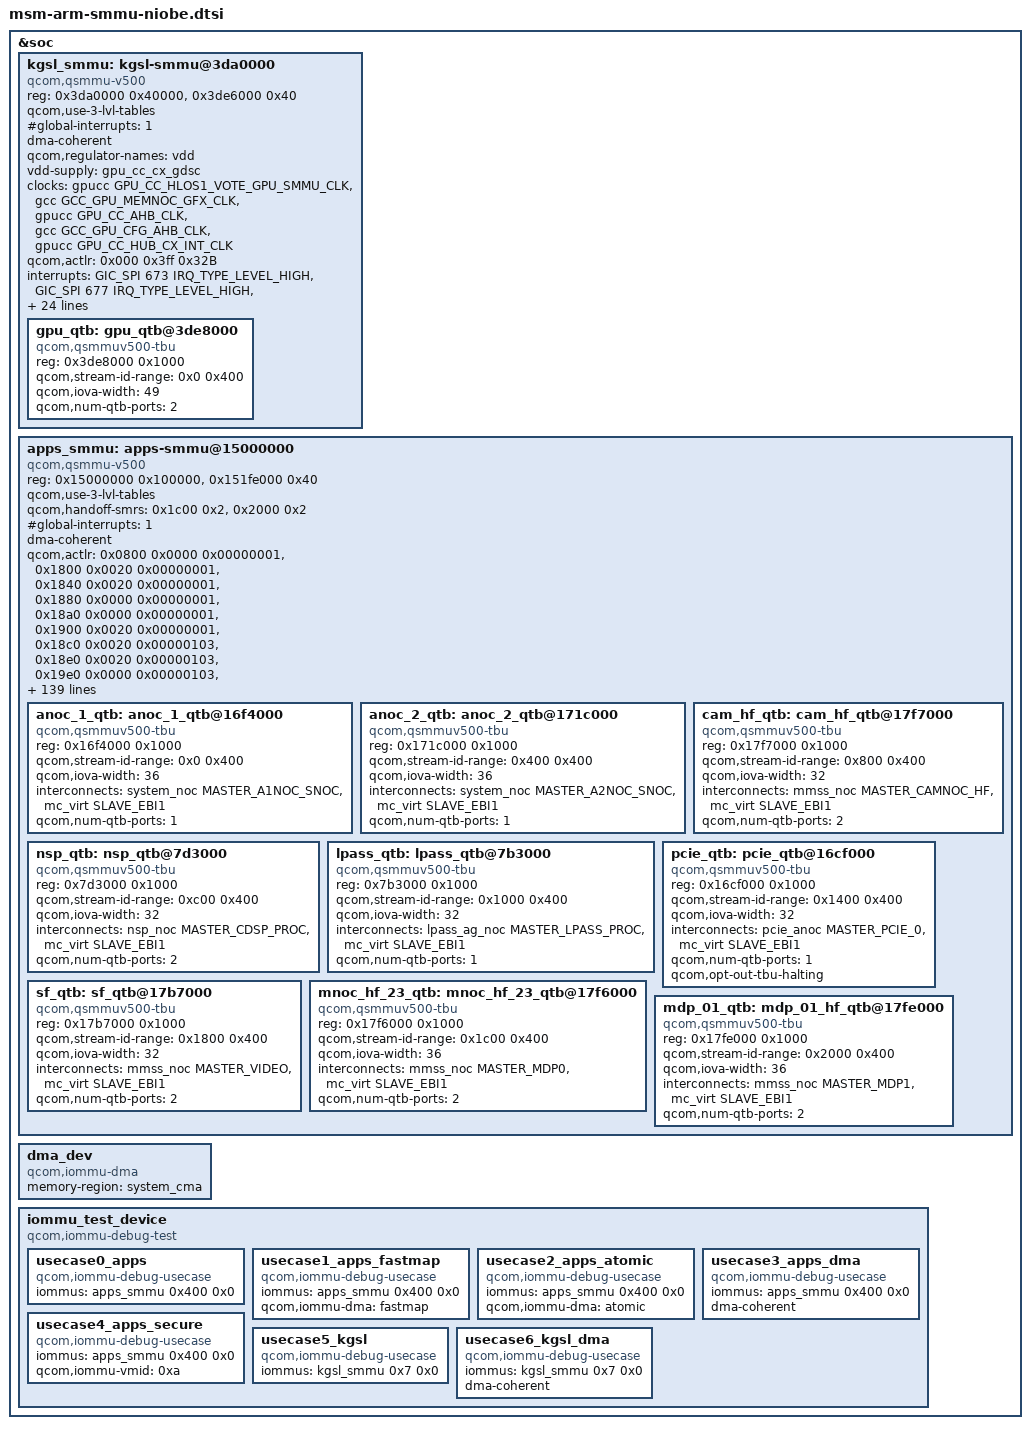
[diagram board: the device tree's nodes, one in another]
#include <dt-bindings/interrupt-controller/arm-gic.h>

&soc {
	kgsl_smmu: kgsl-smmu@3da0000 {
		compatible = "qcom,qsmmu-v500", "qcom,adreno-smmu";
		reg = <0x3da0000 0x40000>,
		    <0x3de6000 0x40>;
		reg-names = "base", "tcu-base";
		#iommu-cells = <2>;
		qcom,use-3-lvl-tables;
		#global-interrupts = <1>;
		#size-cells = <1>;
		#address-cells = <1>;
		ranges;
		dma-coherent;

		qcom,regulator-names = "vdd";
		vdd-supply = <&gpu_cc_cx_gdsc>;

		clocks = <&gpucc GPU_CC_HLOS1_VOTE_GPU_SMMU_CLK>,
		       <&gcc GCC_GPU_MEMNOC_GFX_CLK>,
		       <&gpucc GPU_CC_AHB_CLK>,
		       <&gcc GCC_GPU_CFG_AHB_CLK>,
		       <&gpucc GPU_CC_HUB_CX_INT_CLK>;
		clock-names =
			"gpu_cc_hlos1_vote_gpu_smmu",
			"gcc_gpu_memnoc_gfx",
			"gpu_cc_ahb",
			"gcc_gpu_cfg_ahb",
			"gpu_cc_hub_cx_int";

		qcom,actlr =
			/* All CBs of GFX: +15 deep PF */
			<0x000 0x3ff 0x32B>;

		interrupts =    <GIC_SPI 673 IRQ_TYPE_LEVEL_HIGH>,
				<GIC_SPI 677 IRQ_TYPE_LEVEL_HIGH>,
				<GIC_SPI 678 IRQ_TYPE_LEVEL_HIGH>,
				<GIC_SPI 679 IRQ_TYPE_LEVEL_HIGH>,
				<GIC_SPI 680 IRQ_TYPE_LEVEL_HIGH>,
				<GIC_SPI 681 IRQ_TYPE_LEVEL_HIGH>,
				<GIC_SPI 682 IRQ_TYPE_LEVEL_HIGH>,
				<GIC_SPI 683 IRQ_TYPE_LEVEL_HIGH>,
				<GIC_SPI 684 IRQ_TYPE_LEVEL_HIGH>,
				<GIC_SPI 685 IRQ_TYPE_LEVEL_HIGH>,
				<GIC_SPI 686 IRQ_TYPE_LEVEL_HIGH>,
				<GIC_SPI 687 IRQ_TYPE_LEVEL_HIGH>,
				<GIC_SPI 422 IRQ_TYPE_LEVEL_HIGH>,
				<GIC_SPI 476 IRQ_TYPE_LEVEL_HIGH>,
				<GIC_SPI 574 IRQ_TYPE_LEVEL_HIGH>,
				<GIC_SPI 575 IRQ_TYPE_LEVEL_HIGH>,
				<GIC_SPI 576 IRQ_TYPE_LEVEL_HIGH>,
				<GIC_SPI 577 IRQ_TYPE_LEVEL_HIGH>,
				<GIC_SPI 641 IRQ_TYPE_LEVEL_HIGH>,
				<GIC_SPI 661 IRQ_TYPE_LEVEL_HIGH>,
				<GIC_SPI 664 IRQ_TYPE_LEVEL_HIGH>,
				<GIC_SPI 665 IRQ_TYPE_LEVEL_HIGH>,
				<GIC_SPI 666 IRQ_TYPE_LEVEL_HIGH>,
				<GIC_SPI 668 IRQ_TYPE_LEVEL_HIGH>,
				<GIC_SPI 669 IRQ_TYPE_LEVEL_HIGH>,
				<GIC_SPI 699 IRQ_TYPE_LEVEL_HIGH>;

		gpu_qtb: gpu_qtb@3de8000 {
			compatible = "qcom,qsmmuv500-tbu", "qcom,qtb500";
			reg = <0x3de8000 0x1000>;
			qcom,stream-id-range = <0x0 0x400>;
			qcom,iova-width = <49>;
			qcom,num-qtb-ports = <2>;
		};
	};

	apps_smmu: apps-smmu@15000000 {
		compatible = "qcom,qsmmu-v500";
		reg = <0x15000000 0x100000>,
		    <0x151fe000 0x40>;
		reg-names = "base", "tcu-base";
		#iommu-cells = <2>;
		qcom,use-3-lvl-tables;
		qcom,handoff-smrs = <0x1c00 0x2>,
			<0x2000 0x2>;
		#global-interrupts = <1>;
		#size-cells = <1>;
		#address-cells = <1>;
		ranges;
		dma-coherent;

		qcom,actlr =
			/* Camera */
			<0x0800 0x0000 0x00000001>,
			<0x1800 0x0020 0x00000001>,
			<0x1840 0x0020 0x00000001>,
			<0x1880 0x0000 0x00000001>,
			<0x18a0 0x0000 0x00000001>,
			<0x1900 0x0020 0x00000001>,

			/* Camera JPEG */
			<0x18c0 0x0020 0x00000103>,
			<0x18e0 0x0020 0x00000103>,
			<0x19e0 0x0000 0x00000103>,
			<0x1a00 0x0040 0x00000103>,
			<0x1a20 0x0000 0x00000103>,
			<0x1a40 0x0040 0x00000103>,

			/* Compute */
			<0x0c01 0x0040 0x00000303>,
			<0x0c02 0x0040 0x00000303>,
			<0x0c03 0x0040 0x00000303>,
			<0x0c04 0x0040 0x00000303>,
			<0x0c05 0x0040 0x00000303>,
			<0x0c06 0x0040 0x00000303>,
			<0x0c07 0x0040 0x00000303>,
			<0x0c08 0x0040 0x00000303>,
			<0x0c09 0x0040 0x00000303>,
			<0x0c0b 0x0000 0x00000303>,
			<0x0c0c 0x0040 0x00000303>,
			<0x0c0d 0x0040 0x00000303>,
			<0x0c0e 0x0040 0x00000303>,
			<0x0c21 0x0000 0x00000303>,
			<0x0c22 0x0000 0x00000303>,
			<0x0c23 0x0000 0x00000303>,
			<0x0c24 0x0000 0x00000303>,
			<0x0c25 0x0000 0x00000303>,
			<0x0c26 0x0000 0x00000303>,
			<0x0c27 0x0000 0x00000303>,
			<0x0c28 0x0000 0x00000303>,
			<0x0c29 0x0000 0x00000303>,
			<0x0c2c 0x0000 0x00000303>,
			<0x0c2d 0x0000 0x00000303>,
			<0x0c2e 0x0000 0x00000303>,

			/* Display */
			<0x1c00 0x0002 0x00000001>,
			<0x1c01 0x0000 0x00000001>,
			<0x1c04 0x0002 0x00000001>,
			<0x2000 0x0002 0x00000001>,
			<0x2001 0x0000 0x00000001>,
			<0x2004 0x0002 0x00000001>,

			/* EVA */
			<0x19a0 0x0000 0x00000103>,
			<0x19a3 0x0000 0x00000103>,
			<0x19a4 0x0000 0x00000103>,

			/* Video */
			<0x1980 0x0000 0x00000103>,
			<0x1981 0x0004 0x00000103>,
			<0x1983 0x0000 0x00000103>,
			<0x1984 0x0000 0x00000103>,
			<0x1987 0x0000 0x00000103>;

		interrupts =    <GIC_SPI 65 IRQ_TYPE_LEVEL_HIGH>,
				<GIC_SPI 97 IRQ_TYPE_LEVEL_HIGH>,
				<GIC_SPI 98 IRQ_TYPE_LEVEL_HIGH>,
				<GIC_SPI 99 IRQ_TYPE_LEVEL_HIGH>,
				<GIC_SPI 100 IRQ_TYPE_LEVEL_HIGH>,
				<GIC_SPI 101 IRQ_TYPE_LEVEL_HIGH>,
				<GIC_SPI 102 IRQ_TYPE_LEVEL_HIGH>,
				<GIC_SPI 103 IRQ_TYPE_LEVEL_HIGH>,
				<GIC_SPI 104 IRQ_TYPE_LEVEL_HIGH>,
				<GIC_SPI 105 IRQ_TYPE_LEVEL_HIGH>,
				<GIC_SPI 106 IRQ_TYPE_LEVEL_HIGH>,
				<GIC_SPI 107 IRQ_TYPE_LEVEL_HIGH>,
				<GIC_SPI 108 IRQ_TYPE_LEVEL_HIGH>,
				<GIC_SPI 109 IRQ_TYPE_LEVEL_HIGH>,
				<GIC_SPI 110 IRQ_TYPE_LEVEL_HIGH>,
				<GIC_SPI 111 IRQ_TYPE_LEVEL_HIGH>,
				<GIC_SPI 112 IRQ_TYPE_LEVEL_HIGH>,
				<GIC_SPI 113 IRQ_TYPE_LEVEL_HIGH>,
				<GIC_SPI 114 IRQ_TYPE_LEVEL_HIGH>,
				<GIC_SPI 115 IRQ_TYPE_LEVEL_HIGH>,
				<GIC_SPI 116 IRQ_TYPE_LEVEL_HIGH>,
				<GIC_SPI 117 IRQ_TYPE_LEVEL_HIGH>,
				<GIC_SPI 118 IRQ_TYPE_LEVEL_HIGH>,
				<GIC_SPI 181 IRQ_TYPE_LEVEL_HIGH>,
				<GIC_SPI 182 IRQ_TYPE_LEVEL_HIGH>,
				<GIC_SPI 183 IRQ_TYPE_LEVEL_HIGH>,
				<GIC_SPI 184 IRQ_TYPE_LEVEL_HIGH>,
				<GIC_SPI 185 IRQ_TYPE_LEVEL_HIGH>,
				<GIC_SPI 186 IRQ_TYPE_LEVEL_HIGH>,
				<GIC_SPI 187 IRQ_TYPE_LEVEL_HIGH>,
				<GIC_SPI 188 IRQ_TYPE_LEVEL_HIGH>,
				<GIC_SPI 189 IRQ_TYPE_LEVEL_HIGH>,
				<GIC_SPI 190 IRQ_TYPE_LEVEL_HIGH>,
				<GIC_SPI 191 IRQ_TYPE_LEVEL_HIGH>,
				<GIC_SPI 192 IRQ_TYPE_LEVEL_HIGH>,
				<GIC_SPI 315 IRQ_TYPE_LEVEL_HIGH>,
				<GIC_SPI 316 IRQ_TYPE_LEVEL_HIGH>,
				<GIC_SPI 317 IRQ_TYPE_LEVEL_HIGH>,
				<GIC_SPI 318 IRQ_TYPE_LEVEL_HIGH>,
				<GIC_SPI 319 IRQ_TYPE_LEVEL_HIGH>,
				<GIC_SPI 320 IRQ_TYPE_LEVEL_HIGH>,
				<GIC_SPI 321 IRQ_TYPE_LEVEL_HIGH>,
				<GIC_SPI 322 IRQ_TYPE_LEVEL_HIGH>,
				<GIC_SPI 323 IRQ_TYPE_LEVEL_HIGH>,
				<GIC_SPI 324 IRQ_TYPE_LEVEL_HIGH>,
				<GIC_SPI 325 IRQ_TYPE_LEVEL_HIGH>,
				<GIC_SPI 326 IRQ_TYPE_LEVEL_HIGH>,
				<GIC_SPI 327 IRQ_TYPE_LEVEL_HIGH>,
				<GIC_SPI 328 IRQ_TYPE_LEVEL_HIGH>,
				<GIC_SPI 329 IRQ_TYPE_LEVEL_HIGH>,
				<GIC_SPI 330 IRQ_TYPE_LEVEL_HIGH>,
				<GIC_SPI 331 IRQ_TYPE_LEVEL_HIGH>,
				<GIC_SPI 332 IRQ_TYPE_LEVEL_HIGH>,
				<GIC_SPI 333 IRQ_TYPE_LEVEL_HIGH>,
				<GIC_SPI 334 IRQ_TYPE_LEVEL_HIGH>,
				<GIC_SPI 335 IRQ_TYPE_LEVEL_HIGH>,
				<GIC_SPI 336 IRQ_TYPE_LEVEL_HIGH>,
				<GIC_SPI 337 IRQ_TYPE_LEVEL_HIGH>,
				<GIC_SPI 338 IRQ_TYPE_LEVEL_HIGH>,
				<GIC_SPI 339 IRQ_TYPE_LEVEL_HIGH>,
				<GIC_SPI 340 IRQ_TYPE_LEVEL_HIGH>,
				<GIC_SPI 341 IRQ_TYPE_LEVEL_HIGH>,
				<GIC_SPI 342 IRQ_TYPE_LEVEL_HIGH>,
				<GIC_SPI 343 IRQ_TYPE_LEVEL_HIGH>,
				<GIC_SPI 344 IRQ_TYPE_LEVEL_HIGH>,
				<GIC_SPI 345 IRQ_TYPE_LEVEL_HIGH>,
				<GIC_SPI 395 IRQ_TYPE_LEVEL_HIGH>,
				<GIC_SPI 396 IRQ_TYPE_LEVEL_HIGH>,
				<GIC_SPI 397 IRQ_TYPE_LEVEL_HIGH>,
				<GIC_SPI 398 IRQ_TYPE_LEVEL_HIGH>,
				<GIC_SPI 399 IRQ_TYPE_LEVEL_HIGH>,
				<GIC_SPI 400 IRQ_TYPE_LEVEL_HIGH>,
				<GIC_SPI 401 IRQ_TYPE_LEVEL_HIGH>,
				<GIC_SPI 402 IRQ_TYPE_LEVEL_HIGH>,
				<GIC_SPI 403 IRQ_TYPE_LEVEL_HIGH>,
				<GIC_SPI 404 IRQ_TYPE_LEVEL_HIGH>,
				<GIC_SPI 405 IRQ_TYPE_LEVEL_HIGH>,
				<GIC_SPI 406 IRQ_TYPE_LEVEL_HIGH>,
				<GIC_SPI 407 IRQ_TYPE_LEVEL_HIGH>,
				<GIC_SPI 408 IRQ_TYPE_LEVEL_HIGH>,
				<GIC_SPI 409 IRQ_TYPE_LEVEL_HIGH>,
				<GIC_SPI 418 IRQ_TYPE_LEVEL_HIGH>,
				<GIC_SPI 419 IRQ_TYPE_LEVEL_HIGH>,
				<GIC_SPI 412 IRQ_TYPE_LEVEL_HIGH>,
				<GIC_SPI 421 IRQ_TYPE_LEVEL_HIGH>,
				<GIC_SPI 706 IRQ_TYPE_LEVEL_HIGH>,
				<GIC_SPI 423 IRQ_TYPE_LEVEL_HIGH>,
				<GIC_SPI 424 IRQ_TYPE_LEVEL_HIGH>,
				<GIC_SPI 425 IRQ_TYPE_LEVEL_HIGH>,
				<GIC_SPI 689 IRQ_TYPE_LEVEL_HIGH>,
				<GIC_SPI 690 IRQ_TYPE_LEVEL_HIGH>,
				<GIC_SPI 691 IRQ_TYPE_LEVEL_HIGH>,
				<GIC_SPI 692 IRQ_TYPE_LEVEL_HIGH>,
				<GIC_SPI 693 IRQ_TYPE_LEVEL_HIGH>,
				<GIC_SPI 694 IRQ_TYPE_LEVEL_HIGH>,
				<GIC_SPI 695 IRQ_TYPE_LEVEL_HIGH>,
				<GIC_SPI 696 IRQ_TYPE_LEVEL_HIGH>;

		anoc_1_qtb: anoc_1_qtb@16f4000 {
			compatible = "qcom,qsmmuv500-tbu", "qcom,qtb500";
			reg = <0x16f4000 0x1000>;
			qcom,stream-id-range = <0x0 0x400>;
			qcom,iova-width = <36>;
			interconnects = <&system_noc MASTER_A1NOC_SNOC &mc_virt SLAVE_EBI1>;
			qcom,num-qtb-ports = <1>;
		};

		anoc_2_qtb: anoc_2_qtb@171c000 {
			compatible = "qcom,qsmmuv500-tbu", "qcom,qtb500";
			reg = <0x171c000 0x1000>;
			qcom,stream-id-range = <0x400 0x400>;
			qcom,iova-width = <36>;
			interconnects = <&system_noc MASTER_A2NOC_SNOC &mc_virt SLAVE_EBI1>;
			qcom,num-qtb-ports = <1>;
		};

		cam_hf_qtb: cam_hf_qtb@17f7000 {
			compatible = "qcom,qsmmuv500-tbu", "qcom,qtb500";
			reg = <0x17f7000 0x1000>;
			qcom,stream-id-range = <0x800 0x400>;
			qcom,iova-width = <32>;
			interconnects = <&mmss_noc MASTER_CAMNOC_HF &mc_virt SLAVE_EBI1>;
			qcom,num-qtb-ports = <2>;
		};

		nsp_qtb: nsp_qtb@7d3000 {
			compatible = "qcom,qsmmuv500-tbu", "qcom,qtb500";
			reg = <0x7d3000 0x1000>;
			qcom,stream-id-range = <0xc00 0x400>;
			qcom,iova-width = <32>;
			interconnects = <&nsp_noc MASTER_CDSP_PROC &mc_virt SLAVE_EBI1>;
			qcom,num-qtb-ports = <2>;
		};

		lpass_qtb: lpass_qtb@7b3000 {
			compatible = "qcom,qsmmuv500-tbu", "qcom,qtb500";
			reg = <0x7b3000 0x1000>;
			qcom,stream-id-range = <0x1000 0x400>;
			qcom,iova-width = <32>;
			interconnects = <&lpass_ag_noc MASTER_LPASS_PROC &mc_virt SLAVE_EBI1>;
			qcom,num-qtb-ports = <1>;
		};

		pcie_qtb: pcie_qtb@16cf000 {
			compatible = "qcom,qsmmuv500-tbu", "qcom,qtb500";
			reg = <0x16cf000 0x1000>;
			qcom,stream-id-range = <0x1400 0x400>;
			qcom,iova-width = <32>;
			interconnects = <&pcie_anoc MASTER_PCIE_0 &mc_virt SLAVE_EBI1>;
			qcom,num-qtb-ports = <1>;
			qcom,opt-out-tbu-halting;
		};

		sf_qtb: sf_qtb@17b7000 {
			compatible = "qcom,qsmmuv500-tbu", "qcom,qtb500";
			reg = <0x17b7000 0x1000>;
			qcom,stream-id-range = <0x1800 0x400>;
			qcom,iova-width = <32>;
			interconnects = <&mmss_noc MASTER_VIDEO &mc_virt SLAVE_EBI1>;
			qcom,num-qtb-ports = <2>;
		};

		mnoc_hf_23_qtb: mnoc_hf_23_qtb@17f6000 {
			compatible = "qcom,qsmmuv500-tbu", "qcom,qtb500";
			reg = <0x17f6000 0x1000>;
			qcom,stream-id-range = <0x1c00 0x400>;
			qcom,iova-width = <36>;
			interconnects = <&mmss_noc MASTER_MDP0 &mc_virt SLAVE_EBI1>;
			qcom,num-qtb-ports = <2>;
		};

		mdp_01_qtb: mdp_01_hf_qtb@17fe000 {
			compatible = "qcom,qsmmuv500-tbu", "qcom,qtb500";
			reg = <0x17fe000 0x1000>;
			qcom,stream-id-range = <0x2000 0x400>;
			qcom,iova-width = <36>;
			interconnects = <&mmss_noc MASTER_MDP1 &mc_virt SLAVE_EBI1>;
			qcom,num-qtb-ports = <2>;
		};
	};

	dma_dev {
		compatible = "qcom,iommu-dma";
		memory-region = <&system_cma>;
	};

	iommu_test_device {
		compatible = "qcom,iommu-debug-test";

		usecase0_apps {
			compatible = "qcom,iommu-debug-usecase";
			iommus = <&apps_smmu 0x400 0x0>;
		};

		usecase1_apps_fastmap {
			compatible = "qcom,iommu-debug-usecase";
			iommus = <&apps_smmu 0x400 0x0>;
			qcom,iommu-dma = "fastmap";
		};

		usecase2_apps_atomic {
			compatible = "qcom,iommu-debug-usecase";
			iommus = <&apps_smmu 0x400 0x0>;
			qcom,iommu-dma = "atomic";
		};

		usecase3_apps_dma {
			compatible = "qcom,iommu-debug-usecase";
			iommus = <&apps_smmu 0x400 0x0>;
			dma-coherent;
		};

		usecase4_apps_secure {
			compatible = "qcom,iommu-debug-usecase";
			iommus = <&apps_smmu 0x400 0x0>;
			qcom,iommu-vmid = <0xa>; /* VMID_CP_PIXEL */
		};

		usecase5_kgsl {
			compatible = "qcom,iommu-debug-usecase";
			iommus = <&kgsl_smmu 0x7 0x0>;
		};

		usecase6_kgsl_dma {
			compatible = "qcom,iommu-debug-usecase";
			iommus = <&kgsl_smmu 0x7 0x0>;
			dma-coherent;
		};
	};
};
